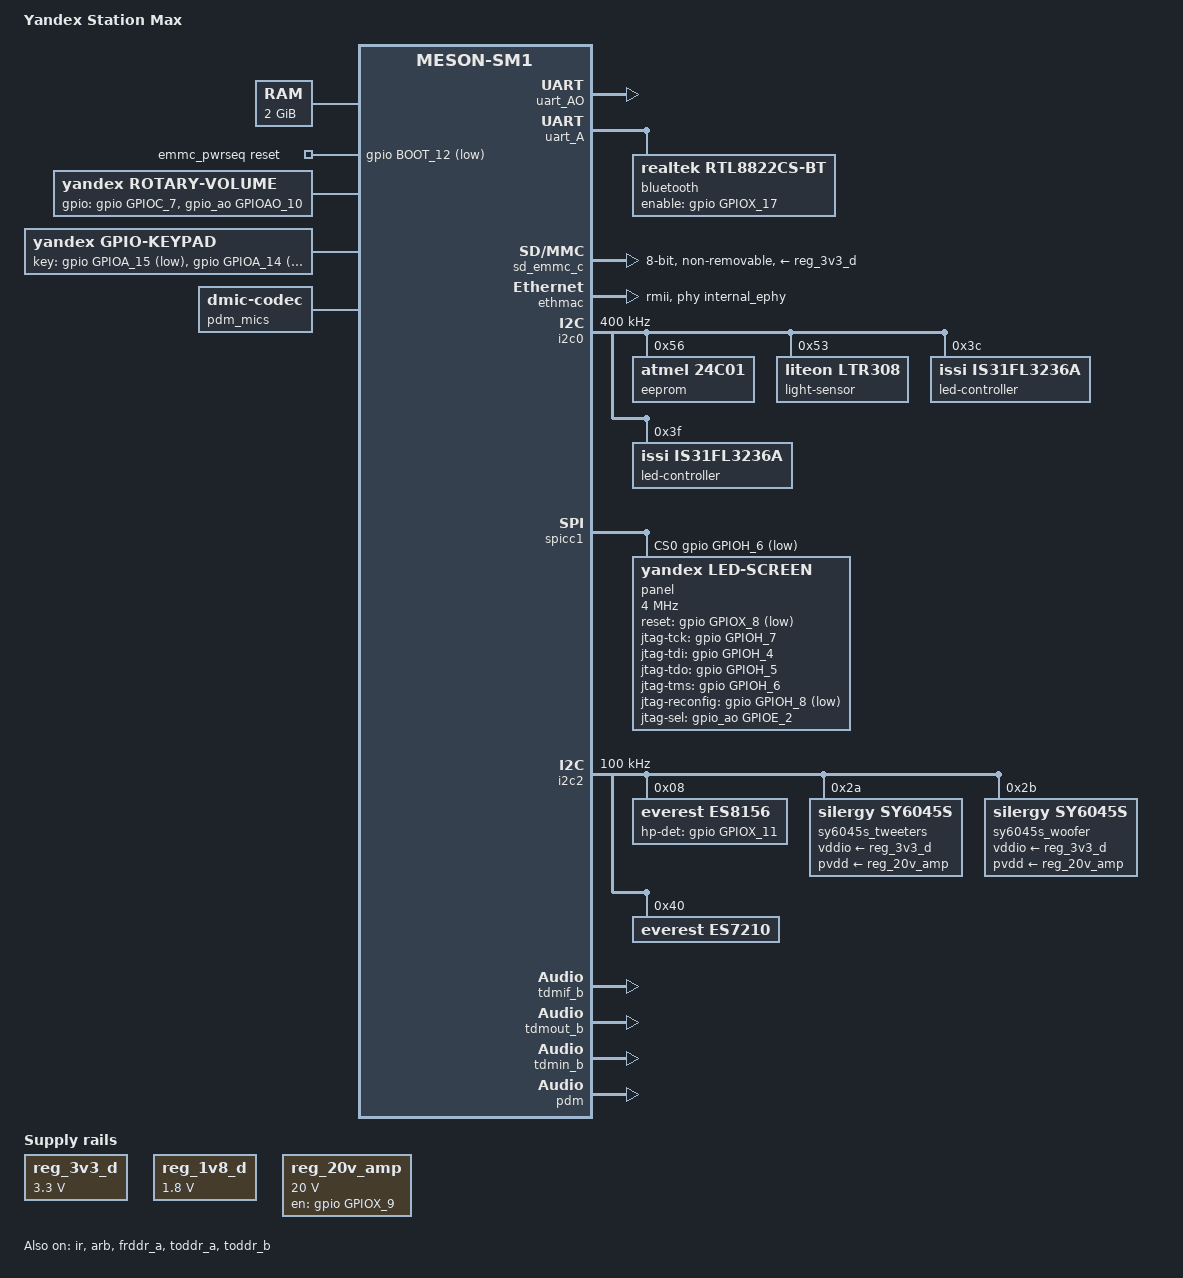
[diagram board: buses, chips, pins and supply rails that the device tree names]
// SPDX-License-Identifier: (GPL-2.0+ OR MIT)
/*
 * Yandex Station Max - Amlogic S905X3 (SM1)
 *
 * GENERATED FILE - do not edit.  Change gen-ring-nodes.py and re-run it.
 *
 * Mainline port; the LED ring nodes at the end of &i2c0 are generated.
 * GPIO/pin/data references:
 *   vendor DTB  AtriOS-linux/common/arch/arm64/boot/dts/amlogic/
 *               sm1_s905x3_yandex.dts (decompiled, phandle numbering is
 *               off by one for the periphs bank: vendor = mainline + 1)
 *   details      mainline/docs/dts-review.md
 */

/dts-v1/;

#include <dt-bindings/gpio/gpio.h>
#include <dt-bindings/gpio/meson-g12a-gpio.h>
#include <dt-bindings/input/input.h>
#include <dt-bindings/interrupt-controller/irq.h>
#include "meson-sm1.dtsi"

/ {
	model = "Yandex Station Max";
	compatible = "yandex,station-max", "amlogic,sm1";

	aliases {
		serial0 = &uart_AO;
		serial1 = &uart_A;
		/* the board boots from eMMC, keep it as mmcblk0 */
		mmc0 = &sd_emmc_c;
		mmc1 = &sd_emmc_b;
		mmc2 = &sd_emmc_a;
		ethernet0 = &ethmac;
	};

	chosen {
		stdout-path = "serial0:115200n8";
	};

	memory@0 {
		device_type = "memory";
		reg = <0x0 0x0 0x0 0x80000000>;
	};

	/*
	 * PMIC-less board: every rail is a fixed, always-on regulator and is
	 * only described so that the consumers below have a supply to point at.
	 * Names follow the vendor DT (fixedregulator-3v3d / -1v8d / -20v-amp).
	 */
	reg_3v3_d: regulator-3v3-d {
		compatible = "regulator-fixed";
		regulator-name = "3V3_D";
		regulator-min-microvolt = <3300000>;
		regulator-max-microvolt = <3300000>;
		regulator-always-on;
	};

	reg_1v8_d: regulator-1v8-d {
		compatible = "regulator-fixed";
		regulator-name = "1V8_D";
		regulator-min-microvolt = <1800000>;
		regulator-max-microvolt = <1800000>;
		regulator-always-on;
	};

	reg_20v_amp: regulator-20v-amp {
		compatible = "regulator-fixed";
		regulator-name = "20V_AMPL";
		regulator-min-microvolt = <20000000>;
		regulator-max-microvolt = <20000000>;
		gpios = <&gpio GPIOX_9 GPIO_ACTIVE_HIGH>;
		enable-active-high;
		regulator-boot-on;
		regulator-always-on;
	};

	/* Vendor emmc node: hw_reset = <&gpio BOOT_12 ...> */
	emmc_pwrseq: emmc-pwrseq {
		compatible = "mmc-pwrseq-emmc";
		reset-gpios = <&gpio BOOT_12 GPIO_ACTIVE_LOW>;
	};

	/* drivers/leds/trigger/ledtrig-ringfb.c */
	led-ring-fb {
		compatible = "yandex,led-ring-fb";
	};

	/*
	 * Vendor DT: compatible = "rotary-volume", gpios = <GPIOC_7>, <GPIOAO_10>,
	 * key-codes = <0x68 0x6d>; the vendor userspace (/usr/lib/atrios/rotaryd)
	 * listens for KEY_PAGEUP/KEY_PAGEDOWN, so the codes must not be changed
	 * to KEY_VOLUMEUP/KEY_VOLUMEDOWN without touching userspace.
	 */
	rotary-volume {
		compatible = "yandex,rotary-volume";
		gpios = <&gpio GPIOC_7 GPIO_ACTIVE_HIGH>,
			<&gpio_ao GPIOAO_10 GPIO_ACTIVE_HIGH>;
		key-codes = <KEY_PAGEUP KEY_PAGEDOWN>;
	};

	/* Vendor gpio_keypad: key_name = "function", "micmute";
	 * key_code = <0x246 0xf8>; key-gpios = GPIOA_15, GPIOA_14 (active low).
	 */
	keypad {
		compatible = "yandex,gpio-keypad";
		key_num = <2>;
		key-names = "function", "micmute";
		key-codes = <KEY_VOICECOMMAND KEY_MICMUTE>;
		key-gpios = <&gpio GPIOA_15 GPIO_ACTIVE_LOW>,
			    <&gpio GPIOA_14 GPIO_ACTIVE_LOW>;
		scan_period = <20>;
		detect_mode = <0>;
	};
};

/* AO UART, the 4-pin debug header (GPIOAO_0/GPIOAO_1). */
&uart_AO {
	status = "okay";
	pinctrl-0 = <&uart_ao_a_pins>;
	pinctrl-names = "default";
};

/*
 * UART_A drives the RTL8822CS Bluetooth module (vendor: uart_tx_a/rx_a/
 * cts_a/rts_a and bt-dev gpio_reset = GPIOX_17).
 */
&uart_A {
	status = "okay";
	pinctrl-0 = <&uart_a_pins>, <&uart_a_cts_rts_pins>;
	pinctrl-names = "default";
	uart-has-rtscts;

	bluetooth {
		compatible = "realtek,rtl8822cs-bt";
		enable-gpios = <&gpio GPIOX_17 GPIO_ACTIVE_HIGH>;
	};
};

/* eMMC.  Vendor: bus-width 8, 200 MHz, non-removable, MMC_CAP2_HS200. */
&sd_emmc_c {
	status = "okay";
	pinctrl-0 = <&emmc_ctrl_pins>, <&emmc_data_8b_pins>, <&emmc_ds_pins>;
	pinctrl-1 = <&emmc_clk_gate_pins>;
	pinctrl-names = "default", "clk-gate";
	bus-width = <8>;
	max-frequency = <200000000>;
	non-removable;
	disable-wp;
	cap-mmc-highspeed;
	mmc-hs200-1_8v;
	mmc-pwrseq = <&emmc_pwrseq>;
	vmmc-supply = <&reg_3v3_d>;
	vqmmc-supply = <&reg_1v8_d>;
};

/*
 * SD slot.  The vendor DT ships sd@ffe05000 with status = "disabled" and it
 * cannot be enabled here either: sdcard_cmd_c and i2c0_sda_c are the same pad
 * (GPIOC_5) and i2c0 carries the LED ring / EEPROM / light sensor, while
 * i2c0_sck_c (GPIOC_6) would take the card-detect line.  Kept for reference.
 */
&sd_emmc_b {
	status = "disabled";
	pinctrl-0 = <&sdcard_c_pins>;
	pinctrl-1 = <&sdcard_clk_gate_c_pins>;
	pinctrl-names = "default", "clk-gate";
	bus-width = <4>;
	cap-sd-highspeed;
	disable-wp;
	max-frequency = <100000000>;
};

/*
 * 10/100 Ethernet.  Vendor: internal_phy = <1>, i.e. the on-SoC PHY reached
 * through the mdio multiplexer (int_mdio/internal_ephy), not an external
 * RGMII PHY.  No pinctrl here: eth_link_led/eth_act_led are GPIOZ_14/15,
 * which are the same pads as i2c2_sda_z/i2c2_sck_z - the codec bus below.
 * The vendor DT dropped the ethernet pinctrl for exactly this reason
 * ("pinctrl removed to prevent GPIOZ_14/15 collision with i2c2", vendor
 * DTS:380), so the link/activity LEDs are simply not driven on this board.
 */
&ethmac {
	status = "okay";
	phy-mode = "rmii";
	phy-handle = <&internal_ephy>;
};

/*
 * Vendor bus: i2c@1f000 on GPIOC_5/GPIOC_6 at 400 kHz.
 */
&i2c0 {
	status = "okay";
	pinctrl-0 = <&i2c0_sda_c_pins>, <&i2c0_sck_c_pins>;
	pinctrl-names = "default";
	clock-frequency = <400000>;

	/* Vendor: compatible = "24c01", PCBA ids EEPROM. */
	eeprom@56 {
		compatible = "atmel,24c01";
		reg = <0x56>;
		pagesize = <8>;
	};

	/*
	 * Vendor: compatible = "lite-on,ltr308als01".  The part is an
	 * LTR-308ALS-01, which upstream binds as "liteon,ltr308"
	 * (drivers/iio/light/ltrf216a.c) - use the upstream id so no driver
	 * patch is needed.
	 */
	light-sensor@53 {
		compatible = "liteon,ltr308";
		reg = <0x53>;
	};

	/*
	 * IS31FL3236A LED ring controllers.  The "gva" compatible,
	 * reg_offset fallback and max-brightness-scale are vendor
	 * extensions carried by patches/linux/0002-leds-is31fl32xx-gva.patch.
	 */
	led-controller@3c {
		compatible = "issi,is31fl3236a";
		reg = <0x3c>;
		#address-cells = <1>;
		#size-cells = <0>;
		max-brightness-scale = <200>;

		led@1 {
			reg = <1>;
			label = "station2:red:ring1";
			linux,default-trigger = "led_ring_fb";
		};
		led@2 {
			reg = <2>;
			label = "station2:green:ring1";
			linux,default-trigger = "led_ring_fb";
		};
		led@3 {
			reg = <3>;
			label = "station2:blue:ring1";
			linux,default-trigger = "led_ring_fb";
		};
		led@4 {
			reg = <4>;
			label = "station2:red:ring2";
			linux,default-trigger = "led_ring_fb";
		};
		led@5 {
			reg = <5>;
			label = "station2:green:ring2";
			linux,default-trigger = "led_ring_fb";
		};
		led@6 {
			reg = <6>;
			label = "station2:blue:ring2";
			linux,default-trigger = "led_ring_fb";
		};
		led@7 {
			reg = <7>;
			label = "station2:red:ring3";
			linux,default-trigger = "led_ring_fb";
		};
		led@8 {
			reg = <8>;
			label = "station2:green:ring3";
			linux,default-trigger = "led_ring_fb";
		};
		led@9 {
			reg = <9>;
			label = "station2:blue:ring3";
			linux,default-trigger = "led_ring_fb";
		};
		led@10 {
			reg = <10>;
			label = "station2:red:ring4";
			linux,default-trigger = "led_ring_fb";
		};
		led@11 {
			reg = <11>;
			label = "station2:green:ring4";
			linux,default-trigger = "led_ring_fb";
		};
		led@12 {
			reg = <12>;
			label = "station2:blue:ring4";
			linux,default-trigger = "led_ring_fb";
		};
		led@13 {
			reg = <13>;
			label = "station2:red:ring5";
			linux,default-trigger = "led_ring_fb";
		};
		led@14 {
			reg = <14>;
			label = "station2:green:ring5";
			linux,default-trigger = "led_ring_fb";
		};
		led@15 {
			reg = <15>;
			label = "station2:blue:ring5";
			linux,default-trigger = "led_ring_fb";
		};
		led@16 {
			reg = <16>;
			label = "station2:red:ring6";
			linux,default-trigger = "led_ring_fb";
		};
		led@17 {
			reg = <17>;
			label = "station2:green:ring6";
			linux,default-trigger = "led_ring_fb";
		};
		led@18 {
			reg = <18>;
			label = "station2:blue:ring6";
			linux,default-trigger = "led_ring_fb";
		};
		led@19 {
			reg = <19>;
			label = "station2:red:ring7";
			linux,default-trigger = "led_ring_fb";
		};
		led@20 {
			reg = <20>;
			label = "station2:green:ring7";
			linux,default-trigger = "led_ring_fb";
		};
		led@21 {
			reg = <21>;
			label = "station2:blue:ring7";
			linux,default-trigger = "led_ring_fb";
		};
		led@22 {
			reg = <22>;
			label = "station2:red:ring8";
			linux,default-trigger = "led_ring_fb";
		};
		led@23 {
			reg = <23>;
			label = "station2:green:ring8";
			linux,default-trigger = "led_ring_fb";
		};
		led@24 {
			reg = <24>;
			label = "station2:blue:ring8";
			linux,default-trigger = "led_ring_fb";
		};
		led@25 {
			reg = <25>;
			label = "station2:red:ring9";
			linux,default-trigger = "led_ring_fb";
		};
		led@26 {
			reg = <26>;
			label = "station2:green:ring9";
			linux,default-trigger = "led_ring_fb";
		};
		led@27 {
			reg = <27>;
			label = "station2:blue:ring9";
			linux,default-trigger = "led_ring_fb";
		};
		led@28 {
			reg = <28>;
			label = "station2:red:ring10";
			linux,default-trigger = "led_ring_fb";
		};
		led@29 {
			reg = <29>;
			label = "station2:green:ring10";
			linux,default-trigger = "led_ring_fb";
		};
		led@30 {
			reg = <30>;
			label = "station2:blue:ring10";
			linux,default-trigger = "led_ring_fb";
		};
		led@31 {
			reg = <31>;
			label = "station2:red:ring11";
			linux,default-trigger = "led_ring_fb";
		};
		led@32 {
			reg = <32>;
			label = "station2:green:ring11";
			linux,default-trigger = "led_ring_fb";
		};
		led@33 {
			reg = <33>;
			label = "station2:blue:ring11";
			linux,default-trigger = "led_ring_fb";
		};
		led@34 {
			reg = <34>;
			label = "station2:red:ring12";
			linux,default-trigger = "led_ring_fb";
		};
		led@35 {
			reg = <35>;
			label = "station2:green:ring12";
			linux,default-trigger = "led_ring_fb";
		};
		led@36 {
			reg = <36>;
			label = "station2:blue:ring12";
			linux,default-trigger = "led_ring_fb";
		};
	};

	led-controller@3f {
		compatible = "issi,is31fl3236a";
		reg = <0x3f>;
		#address-cells = <1>;
		#size-cells = <0>;
		max-brightness-scale = <200>;

		led@1 {
			reg = <1>;
			label = "station2:red:ring13";
			linux,default-trigger = "led_ring_fb";
		};
		led@2 {
			reg = <2>;
			label = "station2:green:ring13";
			linux,default-trigger = "led_ring_fb";
		};
		led@3 {
			reg = <3>;
			label = "station2:blue:ring13";
			linux,default-trigger = "led_ring_fb";
		};
		led@4 {
			reg = <4>;
			label = "station2:red:ring14";
			linux,default-trigger = "led_ring_fb";
		};
		led@5 {
			reg = <5>;
			label = "station2:green:ring14";
			linux,default-trigger = "led_ring_fb";
		};
		led@6 {
			reg = <6>;
			label = "station2:blue:ring14";
			linux,default-trigger = "led_ring_fb";
		};
		led@7 {
			reg = <7>;
			label = "station2:red:ring15";
			linux,default-trigger = "led_ring_fb";
		};
		led@8 {
			reg = <8>;
			label = "station2:green:ring15";
			linux,default-trigger = "led_ring_fb";
		};
		led@9 {
			reg = <9>;
			label = "station2:blue:ring15";
			linux,default-trigger = "led_ring_fb";
		};
		led@10 {
			reg = <10>;
			label = "station2:red:ring16";
			linux,default-trigger = "led_ring_fb";
		};
		led@11 {
			reg = <11>;
			label = "station2:green:ring16";
			linux,default-trigger = "led_ring_fb";
		};
		led@12 {
			reg = <12>;
			label = "station2:blue:ring16";
			linux,default-trigger = "led_ring_fb";
		};
		led@13 {
			reg = <13>;
			label = "station2:red:ring17";
			linux,default-trigger = "led_ring_fb";
		};
		led@14 {
			reg = <14>;
			label = "station2:green:ring17";
			linux,default-trigger = "led_ring_fb";
		};
		led@15 {
			reg = <15>;
			label = "station2:blue:ring17";
			linux,default-trigger = "led_ring_fb";
		};
		led@16 {
			reg = <16>;
			label = "station2:red:ring18";
			linux,default-trigger = "led_ring_fb";
		};
		led@17 {
			reg = <17>;
			label = "station2:green:ring18";
			linux,default-trigger = "led_ring_fb";
		};
		led@18 {
			reg = <18>;
			label = "station2:blue:ring18";
			linux,default-trigger = "led_ring_fb";
		};
		led@19 {
			reg = <19>;
			label = "station2:red:ring19";
			linux,default-trigger = "led_ring_fb";
		};
		led@20 {
			reg = <20>;
			label = "station2:green:ring19";
			linux,default-trigger = "led_ring_fb";
		};
		led@21 {
			reg = <21>;
			label = "station2:blue:ring19";
			linux,default-trigger = "led_ring_fb";
		};
		led@22 {
			reg = <22>;
			label = "station2:red:ring20";
			linux,default-trigger = "led_ring_fb";
		};
		led@23 {
			reg = <23>;
			label = "station2:green:ring20";
			linux,default-trigger = "led_ring_fb";
		};
		led@24 {
			reg = <24>;
			label = "station2:blue:ring20";
			linux,default-trigger = "led_ring_fb";
		};
		led@25 {
			reg = <25>;
			label = "station2:red:ring21";
			linux,default-trigger = "led_ring_fb";
		};
		led@26 {
			reg = <26>;
			label = "station2:green:ring21";
			linux,default-trigger = "led_ring_fb";
		};
		led@27 {
			reg = <27>;
			label = "station2:blue:ring21";
			linux,default-trigger = "led_ring_fb";
		};
		led@28 {
			reg = <28>;
			label = "station2:red:ring22";
			linux,default-trigger = "led_ring_fb";
		};
		led@29 {
			reg = <29>;
			label = "station2:green:ring22";
			linux,default-trigger = "led_ring_fb";
		};
		led@30 {
			reg = <30>;
			label = "station2:blue:ring22";
			linux,default-trigger = "led_ring_fb";
		};
		led@31 {
			reg = <31>;
			label = "station2:red:ring23";
			linux,default-trigger = "led_ring_fb";
		};
		led@32 {
			reg = <32>;
			label = "station2:green:ring23";
			linux,default-trigger = "led_ring_fb";
		};
		led@33 {
			reg = <33>;
			label = "station2:blue:ring23";
			linux,default-trigger = "led_ring_fb";
		};
		led@34 {
			reg = <34>;
			label = "station2:red:ring24";
			linux,default-trigger = "led_ring_fb";
		};
		led@35 {
			reg = <35>;
			label = "station2:green:ring24";
			linux,default-trigger = "led_ring_fb";
		};
		led@36 {
			reg = <36>;
			label = "station2:blue:ring24";
			linux,default-trigger = "led_ring_fb";
		};
	};
};

/*
 * Front matrix panel (25x16 RGB888, Gowin FPGA) on spicc1.
 *
 * NOTE: the panel shares its pads with the FPGA JTAG lines, so those GPIOs
 * cannot simply be requested next to spicc1:
 *   spi1_mosi = GPIOH_4 = jtag-tdi-gpios
 *   spi1_miso = GPIOH_5 = jtag-tdo-gpios
 *   spi1_clk  = GPIOH_7 = jtag-tck-gpios
 *   spi1_ss0  = GPIOH_6 = cs-gpios and jtag-tms-gpios
 * spicc1_pins muxes H_4/H_5/H_7 to the SPI function and the SPI core owns
 * the H_6 chip select, so the panel driver has to do a pinctrl handoff
 * before it can drive the JTAG lines (see docs/dts-review.md).
 */
&spicc1 {
	status = "okay";
	pinctrl-0 = <&spicc1_pins>;
	pinctrl-names = "default";
	cs-gpios = <&gpio GPIOH_6 GPIO_ACTIVE_LOW>;
	num-cs = <1>;

	panel@0 {
		compatible = "yandex,led-screen", "atri,led-panel";
		reg = <0>;
		spi-max-frequency = <4000000>;
		max-brightness = <200>;
		reset-gpios = <&gpio GPIOX_8 GPIO_ACTIVE_LOW>;
		jtag-tck-gpios = <&gpio GPIOH_7 GPIO_ACTIVE_HIGH>;
		jtag-tdi-gpios = <&gpio GPIOH_4 GPIO_ACTIVE_HIGH>;
		jtag-tdo-gpios = <&gpio GPIOH_5 GPIO_ACTIVE_HIGH>;
		jtag-tms-gpios = <&gpio GPIOH_6 GPIO_ACTIVE_HIGH>;
		jtag-reconfig-gpios = <&gpio GPIOH_8 GPIO_ACTIVE_LOW>;
		jtag-sel-gpios = <&gpio_ao GPIOE_2 GPIO_ACTIVE_HIGH>;
	};
};

/*
 * IR receiver (vendor: rc@0xff808040, remote_ao_input on GPIOAO_5).
 * The vendor NEC keymap is not upstream yet, so no linux,rc-map-name here.
 */
&ir {
	status = "okay";
	pinctrl-0 = <&remote_input_ao_pins>;
	pinctrl-names = "default";
};

/*
 * ------------------------------------------------------------------
 * Audio: ES7210 mics, ES8156 headphone DAC, 2x SY6045S amps, TDM-B,
 * PDM array and the AXG DPCM sound card.
 *
 * Everything here is mainline 7.3 (sound/soc/meson/axg-*.c) plus the
 * in-house codec drivers from mainline/drivers/audio (patches/linux/
 * 0007..0009).  Vendor reference: sm1_s905x3_yandex.dts -
 * i2c@1d000 codecs :2126-2164, auge_sound :4244, audiobus tdm@1 :2391,
 * PDM pinctrl :1342.  Details and the userspace contract:
 * mainline/docs/audio.md
 * ------------------------------------------------------------------
 */

/*
 * Audio clock controller and DDR arbiter.  Both are status = "disabled"
 * in meson-sm1.dtsi while tdmif_b and every FIFO reference them, so
 * without these two nodes the card and the DAIs defer forever.
 */
&clkc_audio {
	status = "okay";
};

&arb {
	status = "okay";
};

/*
 * i2c2 = vendor i2c@1d000 (0xffd1d000), the codec bus; the vendor
 * aliases say so explicitly (i2c2 = "/.../i2c@1d000").
 *
 * Pin conflict: i2c2_sda_z / i2c2_sck_z are GPIOZ_14/15, the same pads
 * as the ethernet link/activity LEDs, which is why &ethmac above no
 * longer claims eth_leds_pins (vendor DTS:380 removed it for the same
 * reason).  The alternative group i2c2_sda_x/sck_x (GPIOX_17/18) is not
 * usable either: GPIOX_17 is the RTL8822CS BT enable line.
 */
&i2c2 {
	status = "okay";
	pinctrl-0 = <&i2c2_sda_z_pins>, <&i2c2_sck_z_pins>;
	pinctrl-names = "default";
	/* vendor: 300 kHz (0x493e0); 100 kHz is the safe bring-up value */
	clock-frequency = <100000>;

	/*
	 * ES8156 headphone DAC.  The sound-name-prefix is load-bearing:
	 * userspace addresses "Headphone DAC Playback Volume" /
	 * "Headphone Headphone Switch" and the card routes through the
	 * "Headphone LOUT"/"Headphone ROUT" widgets.
	 * hp-det: vendor GPIO 77 -> mainline GPIOX_11 (the vendor periphs
	 * bank is one pin higher, see docs/audio.md section 5).
	 */
	es8156: audio-codec@8 {
		compatible = "everest,es8156";
		reg = <0x08>;
		#sound-dai-cells = <0>;
		sound-name-prefix = "Headphone";
		hp-det-gpios = <&gpio GPIOX_11 GPIO_ACTIVE_HIGH>;
		status = "okay";
	};

	/* SY6045S tweeter amp (L/R tweeters). */
	sy6045s_tweeters: audio-codec@2a {
		compatible = "silergy,sy6045s";
		reg = <0x2a>;
		#sound-dai-cells = <0>;
		sound-name-prefix = "Tweeters";
		vddio-supply = <&reg_3v3_d>;
		pvdd-supply = <&reg_20v_amp>;
		/* settings file lives in /lib/firmware */
		firmware-name = "sy6045s-tweeters-settings.txt";
		/* vendor "restore-regs": (addr, size, mask) triplets */
		silergy,restore-regs = <0x07 0x01 0xff 0x06 0x01 0x08>;
		status = "okay";
	};

	/* SY6045S woofer amp, PBTL bridged (subwoofer). */
	sy6045s_woofer: audio-codec@2b {
		compatible = "silergy,sy6045s";
		reg = <0x2b>;
		#sound-dai-cells = <0>;
		sound-name-prefix = "Woofer";
		vddio-supply = <&reg_3v3_d>;
		pvdd-supply = <&reg_20v_amp>;
		firmware-name = "sy6045s-woofer-settings.txt";
		silergy,restore-regs = <0x07 0x01 0xff 0x06 0x01 0x08>;
		pbtl-mode;
		status = "okay";
	};

	/*
	 * ES7210 mic ADC.  The vendor used "everest,es7210_2ch"; the 4ch
	 * generic compatible is a superset and the driver limits itself by
	 * the number of slots.  Prefix "Loopback" keeps the
	 * "Loopback ADC1_MAX_GAIN" control names used by userspace.
	 */
	es7210: audio-codec@40 {
		compatible = "everest,es7210";
		reg = <0x40>;
		#sound-dai-cells = <0>;
		sound-name-prefix = "Loopback";
		status = "okay";
	};
};

/*
 * TDM-B (vendor tdm@1) on the AO pads:
 *   AO_8 = sclk, AO_7 = fs, AO_6 = dout2, AO_4 = din0, AO_9 = mclk0.
 *
 * The pinctrl groups only mux the pads to the audio function; the pad
 * clock muxes in MST_PAD_CTRL0/1 select *which* master drives them and
 * reset to MST_A.  They must be re-parented to MST_B, otherwise the
 * pads stay silent.  This is the real replacement for the vendor
 * /dev/mem poke in /etc/init.d/S03amplifiers and matches what
 * meson-g12a-u200.dts does for TDM-B.  Pad mapping: TDM-B sclk =
 * SCLK pad 1, lrclk = LRCLK pad 1, mclk = MCLK pad 0 (vendor
 * mclk_pad = <0>).
 */
&tdmif_b {
	pinctrl-0 = <&tdm_ao_b_sclk_pins>, <&tdm_ao_b_fs_pins>,
		<&tdm_ao_b_dout2_pins>, <&tdm_ao_b_din0_pins>,
		<&mclk0_ao_pins>;
	pinctrl-names = "default";

	assigned-clocks = <&clkc_audio AUD_CLKID_TDM_MCLK_PAD0>,
		<&clkc_audio AUD_CLKID_TDM_SCLK_PAD1>,
		<&clkc_audio AUD_CLKID_TDM_LRCLK_PAD1>;
	assigned-clock-parents = <&clkc_audio AUD_CLKID_MST_B_MCLK>,
		<&clkc_audio AUD_CLKID_MST_B_SCLK>,
		<&clkc_audio AUD_CLKID_MST_B_LRCLK>;
	assigned-clock-rates = <0>, <0>, <0>;
	status = "okay";
};

&tdmout_b {
	status = "okay";
};

&tdmin_b {
	status = "okay";
};

/*
 * DMA front-ends.  axg-card is a DPCM card, so only frddr/toddr links
 * create PCM devices and they are numbered in this order:
 *   PCM 0 playback -> FRDDR_A -> TDM-B
 *   PCM 1 capture  <- TODDR_A <- TDMIN_B  (es7210)
 *   PCM 2 capture  <- TODDR_B <- PDM
 */
&frddr_a {
	status = "okay";
};

&toddr_a {
	status = "okay";
};

&toddr_b {
	status = "okay";
};

/*
 * PDM array: GPIOC_0..3 = pdm_din0..3_c, GPIOC_4 = pdm_dclk_c, i.e.
 * exactly the vendor "pdmin" pinctrl.  Nothing else in this DTS uses
 * GPIOC_0..4: i2c0 takes GPIOC_5/6, the rotary encoder GPIOC_7, and the
 * only other claimant (the disabled SD node) is never probed.
 */
&pdm {
	pinctrl-0 = <&pdm_din0_c_pins>, <&pdm_din1_c_pins>,
		<&pdm_din2_c_pins>, <&pdm_din3_c_pins>,
		<&pdm_dclk_c_pins>;
	pinctrl-names = "default";
	status = "okay";
};

/ {
	/*
	 * Generic DMIC codec for the PDM link (sound/soc/codecs/dmic.c).
	 * The prefix must not be "PDM": the controller itself already
	 * carries sound-name-prefix = "PDM" in meson-sm1.dtsi and two DAPM
	 * widgets cannot share a name.
	 */
	pdm_mics: audio-codec-pdm {
		compatible = "dmic-codec";
		#sound-dai-cells = <0>;
		sound-name-prefix = "MIC";
	};

	sound {
		compatible = "amlogic,axg-sound-card";
		/* card short name: amixer -c AMLAUGESOUND, plughw:AMLAUGESOUND,0 */
		model = "AML-AUGESOUND";

		/* formatters have to be aux-devs so DAPM can route through them */
		audio-aux-devs = <&tdmout_b>, <&tdmin_b>;
		audio-widgets = "Headphone", "Headphones";

		/*
		 * Interconnect indices are fixed by the audio block: FRDDR_x
		 * OUT n -> TDMOUT (0 = TDM-A, 1 = TDM-B, 2 = TDM-C, 3/4 =
		 * SPDIF), TODDR_x IN n <- TDMIN_B (n = TDM interface index),
		 * TODDR_x IN 4 <- PDM.
		 */
		audio-routing = "TDMOUT_B IN 0", "FRDDR_A OUT 1",
			"TDM_B Playback", "TDMOUT_B OUT",
			"TDMIN_B IN 1", "TDM_B Capture",
			"TODDR_A IN 1", "TDMIN_B OUT",
			"TODDR_B IN 4", "PDM Capture",
			"Headphones", "Headphone LOUT",
			"Headphones", "Headphone ROUT";

		/*
		 * PLL rates copied from meson-g12a-u200.dts: they give the
		 * audio block exact 12.288/24.576 MHz multiples.  Verify with
		 * /sys/kernel/debug/clk/clk_summary on the target; if another
		 * consumer of MPLL0/1/2 shows up these numbers have to move.
		 */
		clocks = <&clkc CLKID_MPLL2>,
			<&clkc CLKID_MPLL0>,
			<&clkc CLKID_MPLL1>;
		assigned-clocks = <&clkc CLKID_MPLL2>,
			<&clkc CLKID_MPLL0>,
			<&clkc CLKID_MPLL1>;
		assigned-clock-rates = <294912000>,
			<270950400>,
			<393216000>;

		dai-link-0 {
			sound-dai = <&frddr_a>;     /* PCM 0 playback */
		};

		dai-link-1 {
			sound-dai = <&toddr_a>;     /* PCM 1 capture */
		};

		dai-link-2 {
			sound-dai = <&toddr_b>;     /* PCM 2 capture */
		};

		/*
		 * TDM-B backend: one bus, four codecs.  Slot masks are per
		 * lane: vendor dai-tdm-lane-slot-mask-out = <0 0 1 0> becomes
		 * tx-mask-2 (lane 2 = AO_6/dout2) and -in = <1 0 0 0> becomes
		 * rx-mask-0 (lane 0 = AO_4/din0).
		 */
		dai-link-3 {
			sound-dai = <&tdmif_b>;
			dai-format = "i2s";
			mclk-fs = <256>;
			dai-tdm-slot-num = <2>;
			dai-tdm-slot-width = <32>;
			dai-tdm-slot-tx-mask-2 = <1 1>;
			dai-tdm-slot-rx-mask-0 = <1 1>;

			codec-0 {
				sound-dai = <&sy6045s_woofer>;
			};
			codec-1 {
				sound-dai = <&sy6045s_tweeters>;
			};
			codec-2 {
				sound-dai = <&es8156>;
			};
			codec-3 {
				/* capture side of the same I2S bus */
				sound-dai = <&es7210>;
			};
		};

		/*
		 * PDM backend.  No mclk-fs here: axg-pdm derives DCLK/SYSCLK
		 * from the stream rate in hw_params and the property would only
		 * be read for tdm-iface links.
		 */
		dai-link-4 {
			sound-dai = <&pdm>;

			codec {
				sound-dai = <&pdm_mics>;
			};
		};
	};
};
